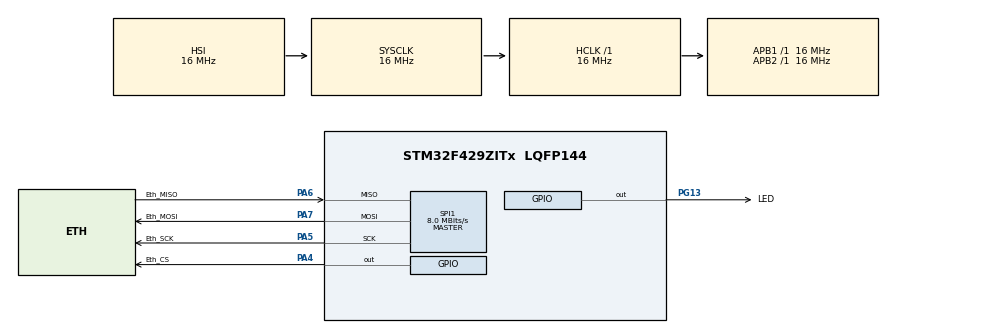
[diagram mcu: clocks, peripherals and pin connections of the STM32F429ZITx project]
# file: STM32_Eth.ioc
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FREERTOS.Tasks01=defaultTask,24,128,StartDefaultTask,Default,NULL,Dynamic,NULL,NULL
FREERTOS.configUSE_NEWLIB_REENTRANT=1
Mcu.Family=STM32F4
Mcu.Name=STM32F429ZITx
Mcu.Package=LQFP144
NVIC.PriorityGroup=NVIC_PRIORITYGROUP_4
NVIC.SPI1_IRQn=true\:5\:0\:false\:false\:true\:true\:true\:true\:true
PA4.GPIO_Label=Eth_CS
PA4.Signal=GPIO_Output
PA5.GPIO_Label=Eth_SCK
PA5.Mode=Full_Duplex_Master
PA5.Signal=SPI1_SCK
PA6.GPIO_Label=Eth_MISO
PA6.Mode=Full_Duplex_Master
PA6.Signal=SPI1_MISO
PA7.GPIO_Label=Eth_MOSI
PA7.Mode=Full_Duplex_Master
PA7.Signal=SPI1_MOSI
PG13.GPIO_Label=LED
PG13.Signal=GPIO_Output
ProjectManager.HeapSize=0x200
ProjectManager.StackSize=0x400
ProjectManager.TargetToolchain=STM32CubeIDE
RCC.AHBFreq_Value=16000000
RCC.APB1Freq_Value=16000000
RCC.APB2Freq_Value=16000000
RCC.CortexFreq_Value=16000000
RCC.HSE_VALUE=25000000
RCC.HSI_VALUE=16000000
RCC.LSE_VALUE=32768
RCC.SYSCLKFreq_VALUE=16000000
RCC.VCOOutputFreq_Value=192000000
SPI1.CalculateBaudRate=8.0 MBits/s
SPI1.Direction=SPI_DIRECTION_2LINES
SPI1.Mode=SPI_MODE_MASTER
SPI1.VirtualType=VM_MASTER
VP_FREERTOS_VS_CMSIS_V2.Mode=CMSIS_V2
board=custom

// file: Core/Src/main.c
/* USER CODE BEGIN Header */
/**
  ******************************************************************************
  * @file           : main.c
  * @brief          : Main program body
  ******************************************************************************
  * @attention
  *
  * Copyright (c) 2023 STMicroelectronics.
  * All rights reserved.
  *
  * This software is licensed under terms that can be found in the LICENSE file
  * in the root directory of this software component.
  * If no LICENSE file comes with this software, it is provided AS-IS.
  *
  ******************************************************************************
  */
/* USER CODE END Header */
#include "main.h"
#include "cmsis_os.h"
#include "spi.h"
#include "gpio.h"

void SystemClock_Config(void);
void MX_FREERTOS_Init(void);

int main(void)
{

  /* MCU Configuration--------------------------------------------------------*/

  /* Reset of all peripherals, Initializes the Flash interface and the Systick. */
  HAL_Init();

  /* Configure the system clock */
  SystemClock_Config();

  /* Initialize all configured peripherals */
  MX_GPIO_Init();
  MX_SPI1_Init();

  /* Init scheduler */
  osKernelInitialize();  /* Call init function for freertos objects (in freertos.c) */
  MX_FREERTOS_Init();

  /* Start scheduler */
  osKernelStart();

  /* We should never get here as control is now taken by the scheduler */
  /* Infinite loop */
  while (1)
  {

  }
}

void SystemClock_Config(void)
{
  RCC_OscInitTypeDef RCC_OscInitStruct = {0};
  RCC_ClkInitTypeDef RCC_ClkInitStruct = {0};

  /** Configure the main internal regulator output voltage
  */
  __HAL_RCC_PWR_CLK_ENABLE();
  __HAL_PWR_VOLTAGESCALING_CONFIG(PWR_REGULATOR_VOLTAGE_SCALE3);

  /** Initializes the RCC Oscillators according to the specified parameters
  * in the RCC_OscInitTypeDef structure.
  */
  RCC_OscInitStruct.OscillatorType = RCC_OSCILLATORTYPE_HSI;
  RCC_OscInitStruct.HSIState = RCC_HSI_ON;
  RCC_OscInitStruct.HSICalibrationValue = RCC_HSICALIBRATION_DEFAULT;
  RCC_OscInitStruct.PLL.PLLState = RCC_PLL_NONE;
  if (HAL_RCC_OscConfig(&RCC_OscInitStruct) != HAL_OK)
  {
    Error_Handler();
  }

  /** Initializes the CPU, AHB and APB buses clocks
  */
  RCC_ClkInitStruct.ClockType = RCC_CLOCKTYPE_HCLK|RCC_CLOCKTYPE_SYSCLK
                              |RCC_CLOCKTYPE_PCLK1|RCC_CLOCKTYPE_PCLK2;
  RCC_ClkInitStruct.SYSCLKSource = RCC_SYSCLKSOURCE_HSI;
  RCC_ClkInitStruct.AHBCLKDivider = RCC_SYSCLK_DIV1;
  RCC_ClkInitStruct.APB1CLKDivider = RCC_HCLK_DIV1;
  RCC_ClkInitStruct.APB2CLKDivider = RCC_HCLK_DIV1;

  if (HAL_RCC_ClockConfig(&RCC_ClkInitStruct, FLASH_LATENCY_0) != HAL_OK)
  {
    Error_Handler();
  }
}

void Error_Handler(void)
{
  __disable_irq();
  while (1)
  {
  }
}

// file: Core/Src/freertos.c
/* USER CODE BEGIN Header */
/**
  ******************************************************************************
  * File Name          : freertos.c
  * Description        : Code for freertos applications
  ******************************************************************************
  * @attention
  *
  * Copyright (c) 2023 STMicroelectronics.
  * All rights reserved.
  *
  * This software is licensed under terms that can be found in the LICENSE file
  * in the root directory of this software component.
  * If no LICENSE file comes with this software, it is provided AS-IS.
  *
  ******************************************************************************
  */
/* USER CODE END Header */

#include "FreeRTOS.h"
#include "task.h"
#include "main.h"
#include "cmsis_os.h"

/* USER CODE BEGIN Includes */
#include "init_Eth.h"
#include "socket.h"
#include <stdio.h>
#include <string.h>

#define DHCP_SOCKET     0
#define DNS_SOCKET      1
#define HTTP_SOCKET     2

/* USER CODE END Includes */

/* Definitions for defaultTask */
osThreadId_t defaultTaskHandle;
const osThreadAttr_t defaultTask_attributes = {
  .name = "defaultTask",
  .stack_size = 128 * 4,
  .priority = (osPriority_t) osPriorityNormal,
};

void StartDefaultTask(void *argument);

void MX_FREERTOS_Init(void); /* (MISRA C 2004 rule 8.1) */

void MX_FREERTOS_Init(void) {

  /* Create the thread(s) */
  /* creation of defaultTask */
  defaultTaskHandle = osThreadNew(StartDefaultTask, NULL, &defaultTask_attributes);

}

void StartDefaultTask(void *argument)
{
  /* USER CODE BEGIN StartDefaultTask */
  /* Infinite loop */

	IP_set();
	socket_init();

	while(1){
	echo_server();
  }
  /* USER CODE END StartDefaultTask */
}
